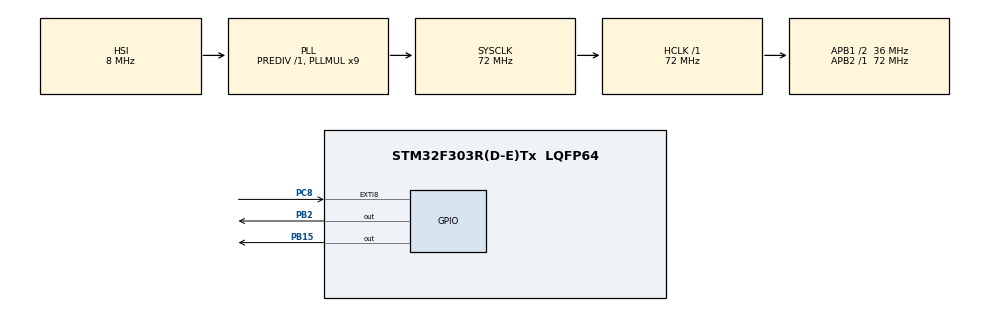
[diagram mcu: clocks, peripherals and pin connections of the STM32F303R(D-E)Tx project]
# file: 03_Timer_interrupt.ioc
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Mcu.Family=STM32F3
Mcu.Name=STM32F303R(D-E)Tx
Mcu.Package=LQFP64
NVIC.PriorityGroup=NVIC_PRIORITYGROUP_4
NVIC.TIM7_IRQn=true\:0\:0\:false\:false\:true\:true
PB11.Signal=TSC_G6_IO1
PB15.Signal=GPIO_Output
PB2.Signal=GPIO_Output
PC8.Signal=GPXTI8
ProjectManager.HeapSize=0x200
ProjectManager.StackSize=0x400
ProjectManager.TargetToolchain=TrueSTUDIO
RCC.AHBFreq_Value=72000000
RCC.APB1CLKDivider=RCC_HCLK_DIV2
RCC.APB1Freq_Value=36000000
RCC.APB1TimFreq_Value=72000000
RCC.APB2Freq_Value=72000000
RCC.APB2TimFreq_Value=72000000
RCC.CortexFreq_Value=72000000
RCC.HCLKFreq_Value=72000000
RCC.HSE_VALUE=8000000
RCC.HSI_VALUE=8000000
RCC.LSE_VALUE=32768
RCC.PLLMUL=RCC_PLL_MUL9
RCC.SYSCLKFreq_VALUE=72000000
RCC.SYSCLKSourceVirtual=RCC_SYSCLKSOURCE_PLLCLK
RCC.USBFreq_Value=72000000
TIM7.Period=3199
TIM7.Prescaler=9999
VP_TIM7_VS_ClockSourceINT.Mode=Enable_Timer
board=03_Timer_interrupt

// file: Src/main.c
/**
  ******************************************************************************
  * @file           : main.c
  * @brief          : Main program body
  ******************************************************************************
  ** This notice applies to any and all portions of this file
  * that are not between comment pairs USER CODE BEGIN and
  * USER CODE END. Other portions of this file, whether
  * inserted by the user or by software development tools
  * are owned by their respective copyright owners.
  *
  * COPYRIGHT(c) 2019 STMicroelectronics
  *
  * Redistribution and use in source and binary forms, with or without modification,
  * are permitted provided that the following conditions are met:
  *   1. Redistributions of source code must retain the above copyright notice,
  *      this list of conditions and the following disclaimer.
  *   2. Redistributions in binary form must reproduce the above copyright notice,
  *      this list of conditions and the following disclaimer in the documentation
  *      and/or other materials provided with the distribution.
  *   3. Neither the name of STMicroelectronics nor the names of its contributors
  *      may be used to endorse or promote products derived from this software
  *      without specific prior written permission.
  *
  * THIS SOFTWARE IS PROVIDED BY THE COPYRIGHT HOLDERS AND CONTRIBUTORS "AS IS"
  * AND ANY EXPRESS OR IMPLIED WARRANTIES, INCLUDING, BUT NOT LIMITED TO, THE
  * IMPLIED WARRANTIES OF MERCHANTABILITY AND FITNESS FOR A PARTICULAR PURPOSE ARE
  * DISCLAIMED. IN NO EVENT SHALL THE COPYRIGHT HOLDER OR CONTRIBUTORS BE LIABLE
  * FOR ANY DIRECT, INDIRECT, INCIDENTAL, SPECIAL, EXEMPLARY, OR CONSEQUENTIAL
  * DAMAGES (INCLUDING, BUT NOT LIMITED TO, PROCUREMENT OF SUBSTITUTE GOODS OR
  * SERVICES; LOSS OF USE, DATA, OR PROFITS; OR BUSINESS INTERRUPTION) HOWEVER
  * CAUSED AND ON ANY THEORY OF LIABILITY, WHETHER IN CONTRACT, STRICT LIABILITY,
  * OR TORT (INCLUDING NEGLIGENCE OR OTHERWISE) ARISING IN ANY WAY OUT OF THE USE
  * OF THIS SOFTWARE, EVEN IF ADVISED OF THE POSSIBILITY OF SUCH DAMAGE.
  *
  ******************************************************************************
  */
#include "main.h"
#include "stm32f3xx_hal.h"

TIM_HandleTypeDef htim7;

/* USER CODE BEGIN PV */
/* Private variables ---------------------------------------------------------*/

/* USER CODE END PV */

void SystemClock_Config(void);
static void MX_GPIO_Init(void);
static void MX_TIM7_Init(void);

/* USER CODE BEGIN PFP */
/* Private function prototypes -----------------------------------------------*/
void HAL_TIM_PeriodElapsedCallback(TIM_HandleTypeDef *htim){
 if(htim->Instance == TIM7){ // Je¿eli przerwanie pochodzi od timera 7
 HAL_GPIO_TogglePin(GPIOB, GPIO_PIN_2);
 }
}
/* USER CODE END PFP */

int main(void)
{

  /* MCU Configuration----------------------------------------------------------*/

  /* Reset of all peripherals, Initializes the Flash interface and the Systick. */
  HAL_Init();

  /* Configure the system clock */
  SystemClock_Config();

  /* Initialize all configured peripherals */
  MX_GPIO_Init();
  MX_TIM7_Init();
  /* USER CODE BEGIN 2 */
  HAL_TIM_Base_Start_IT(&htim7);
  /* USER CODE END 2 */

  /* Infinite loop */
  while (1)
  {

  }

}

void SystemClock_Config(void)
{

  RCC_OscInitTypeDef RCC_OscInitStruct;
  RCC_ClkInitTypeDef RCC_ClkInitStruct;

    /**Initializes the CPU, AHB and APB busses clocks
    */
  RCC_OscInitStruct.OscillatorType = RCC_OSCILLATORTYPE_HSI;
  RCC_OscInitStruct.HSIState = RCC_HSI_ON;
  RCC_OscInitStruct.HSICalibrationValue = 16;
  RCC_OscInitStruct.PLL.PLLState = RCC_PLL_ON;
  RCC_OscInitStruct.PLL.PLLSource = RCC_PLLSOURCE_HSI;
  RCC_OscInitStruct.PLL.PLLMUL = RCC_PLL_MUL9;
  RCC_OscInitStruct.PLL.PREDIV = RCC_PREDIV_DIV1;
  if (HAL_RCC_OscConfig(&RCC_OscInitStruct) != HAL_OK)
  {
    _Error_Handler(__FILE__, __LINE__);
  }

    /**Initializes the CPU, AHB and APB busses clocks
    */
  RCC_ClkInitStruct.ClockType = RCC_CLOCKTYPE_HCLK|RCC_CLOCKTYPE_SYSCLK
                              |RCC_CLOCKTYPE_PCLK1|RCC_CLOCKTYPE_PCLK2;
  RCC_ClkInitStruct.SYSCLKSource = RCC_SYSCLKSOURCE_PLLCLK;
  RCC_ClkInitStruct.AHBCLKDivider = RCC_SYSCLK_DIV1;
  RCC_ClkInitStruct.APB1CLKDivider = RCC_HCLK_DIV2;
  RCC_ClkInitStruct.APB2CLKDivider = RCC_HCLK_DIV1;

  if (HAL_RCC_ClockConfig(&RCC_ClkInitStruct, FLASH_LATENCY_2) != HAL_OK)
  {
    _Error_Handler(__FILE__, __LINE__);
  }

    /**Configure the Systick interrupt time
    */
  HAL_SYSTICK_Config(HAL_RCC_GetHCLKFreq()/1000);

    /**Configure the Systick
    */
  HAL_SYSTICK_CLKSourceConfig(SYSTICK_CLKSOURCE_HCLK);

  /* SysTick_IRQn interrupt configuration */
  HAL_NVIC_SetPriority(SysTick_IRQn, 0, 0);
}

/* TIM7 init function */
static void MX_TIM7_Init(void)
{

  TIM_MasterConfigTypeDef sMasterConfig;

  htim7.Instance = TIM7;
  htim7.Init.Prescaler = 9999;
  htim7.Init.CounterMode = TIM_COUNTERMODE_UP;
  htim7.Init.Period = 3199;
  htim7.Init.AutoReloadPreload = TIM_AUTORELOAD_PRELOAD_DISABLE;
  if (HAL_TIM_Base_Init(&htim7) != HAL_OK)
  {
    _Error_Handler(__FILE__, __LINE__);
  }

  sMasterConfig.MasterOutputTrigger = TIM_TRGO_RESET;
  sMasterConfig.MasterSlaveMode = TIM_MASTERSLAVEMODE_DISABLE;
  if (HAL_TIMEx_MasterConfigSynchronization(&htim7, &sMasterConfig) != HAL_OK)
  {
    _Error_Handler(__FILE__, __LINE__);
  }

}

/** Configure pins as
        * Analog
        * Input
        * Output
        * EVENT_OUT
        * EXTI
     PB11   ------> TSC_G6_IO1
*/
static void MX_GPIO_Init(void)
{

  GPIO_InitTypeDef GPIO_InitStruct;

  /* GPIO Ports Clock Enable */
  __HAL_RCC_GPIOB_CLK_ENABLE();
  __HAL_RCC_GPIOC_CLK_ENABLE();

  /*Configure GPIO pin Output Level */
  HAL_GPIO_WritePin(GPIOB, GPIO_PIN_2|GPIO_PIN_15, GPIO_PIN_RESET);

  /*Configure GPIO pins : PB2 PB15 */
  GPIO_InitStruct.Pin = GPIO_PIN_2|GPIO_PIN_15;
  GPIO_InitStruct.Mode = GPIO_MODE_OUTPUT_PP;
  GPIO_InitStruct.Pull = GPIO_NOPULL;
  GPIO_InitStruct.Speed = GPIO_SPEED_FREQ_LOW;
  HAL_GPIO_Init(GPIOB, &GPIO_InitStruct);

  /*Configure GPIO pin : PB11 */
  GPIO_InitStruct.Pin = GPIO_PIN_11;
  GPIO_InitStruct.Mode = GPIO_MODE_AF_PP;
  GPIO_InitStruct.Pull = GPIO_NOPULL;
  GPIO_InitStruct.Speed = GPIO_SPEED_FREQ_LOW;
  GPIO_InitStruct.Alternate = GPIO_AF3_TSC;
  HAL_GPIO_Init(GPIOB, &GPIO_InitStruct);

  /*Configure GPIO pin : PC8 */
  GPIO_InitStruct.Pin = GPIO_PIN_8;
  GPIO_InitStruct.Mode = GPIO_MODE_IT_RISING;
  GPIO_InitStruct.Pull = GPIO_NOPULL;
  HAL_GPIO_Init(GPIOC, &GPIO_InitStruct);

}

void _Error_Handler(char *file, int line)
{
  while(1)
  {
  }
}

/************************ (C) COPYRIGHT STMicroelectronics *****END OF FILE****/
